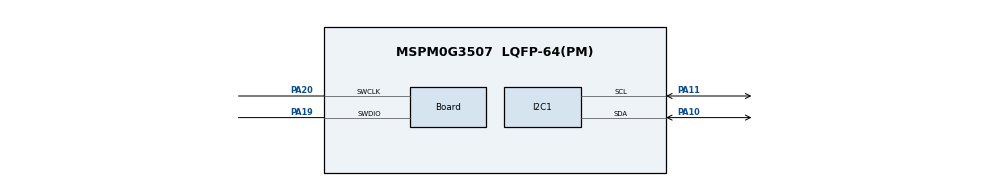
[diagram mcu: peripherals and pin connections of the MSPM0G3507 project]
//@cliArgs --device "MSPM0G350X" --package "LQFP-64(PM)" --part "Default"
//@v2CliArgs --device "MSPM0G3507" --package "LQFP-64(PM)"
// @cliArgs --board /ti/boards/LP_MSPM0G3507 --rtos nortos

/**
 * Import the modules used in this configuration.
 */
const GPIO   = scripting.addModule("/ti/driverlib/GPIO", {}, false);
const GPIO1  = GPIO.addInstance();
const I2C    = scripting.addModule("/ti/driverlib/I2C", {}, false);
const I2C1   = I2C.addInstance();
const SYSCTL = scripting.addModule("/ti/driverlib/SYSCTL");

/**
 * Write custom configuration values to the imported modules.
 */
GPIO1.$name                          = "GROUP0";
GPIO1.associatedPins.create(2);
GPIO1.associatedPins[0].$name        = "IRQ_IN";
GPIO1.associatedPins[0].direction    = "INPUT";
GPIO1.associatedPins[0].assignedPort = "PORTA";
GPIO1.associatedPins[0].interruptEn  = true;
GPIO1.associatedPins[0].polarity     = "FALL";
GPIO1.associatedPins[0].assignedPin  = "12";
GPIO1.associatedPins[1].$name        = "LED";
GPIO1.associatedPins[1].initialValue = "SET";
GPIO1.associatedPins[1].assignedPort = "PORTA";
GPIO1.associatedPins[1].assignedPin  = "0";

const Board                       = scripting.addModule("/ti/driverlib/Board", {}, false);
Board.peripheral.$assign          = "DEBUGSS";
Board.peripheral.swclkPin.$assign = "PA20";
Board.peripheral.swdioPin.$assign = "PA19";

I2C1.basicEnableController             = true;
I2C1.advControllerTXFIFOTRIG           = "BYTES_1";
I2C1.$name                             = "I2C";
I2C1.intController                     = ["NACK","RXFIFO_TRIGGER","RX_DONE","TXFIFO_TRIGGER","TX_DONE"];
I2C1.basicControllerStandardBusSpeed   = "Fast";
I2C1.peripheral.$assign                = "I2C0";
I2C1.peripheral.sdaPin.$assign         = "PA10";
I2C1.peripheral.sclPin.$assign         = "PA11";
I2C1.sdaPinConfig.enableConfig         = true;
I2C1.sdaPinConfig.internalResistor     = "PULL_UP";
I2C1.sclPinConfig.enableConfig         = true;
I2C1.sclPinConfig.internalResistor     = "PULL_UP";

SYSCTL.peripheral.$assign = "SYSCTL";

const ProjectConfig              = scripting.addModule("/ti/project_config/ProjectConfig", {}, false);
ProjectConfig.migrationCondition = true;
